VERSION ""

NS_ :

BS_:

BU_: GWM VCU

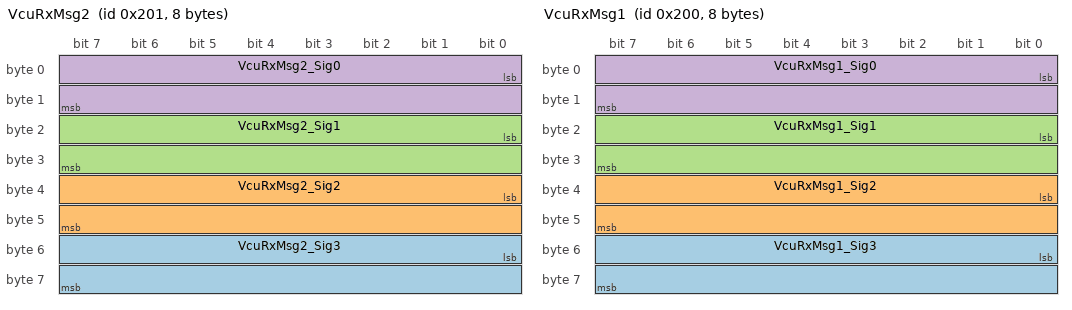
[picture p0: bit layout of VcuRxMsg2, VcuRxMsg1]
BO_ 513 VcuRxMsg2: 8 GWM
 SG_ VcuRxMsg2_Sig3 : 48|16@1- (1,0) [0|0] ""  VCU
 SG_ VcuRxMsg2_Sig2 : 32|16@1- (1,0) [0|0] ""  VCU
 SG_ VcuRxMsg2_Sig1 : 16|16@1- (1,0) [0|0] ""  VCU
 SG_ VcuRxMsg2_Sig0 : 0|16@1- (1,0) [0|0] ""  VCU

BO_ 512 VcuRxMsg1: 8 GWM
 SG_ VcuRxMsg1_Sig3 : 48|16@1- (1,0) [0|0] ""  VCU
 SG_ VcuRxMsg1_Sig2 : 32|16@1- (1,0) [0|0] ""  VCU
 SG_ VcuRxMsg1_Sig1 : 16|16@1- (1,0) [0|0] ""  VCU
 SG_ VcuRxMsg1_Sig0 : 0|16@1- (1,0) [0|0] ""  VCU

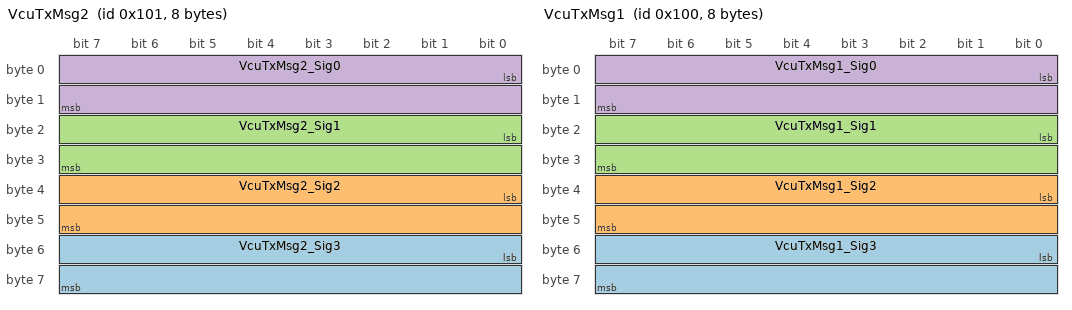
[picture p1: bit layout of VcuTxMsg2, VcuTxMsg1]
BO_ 257 VcuTxMsg2: 8 VCU
 SG_ VcuTxMsg2_Sig3 : 48|16@1- (1,0) [0|0] ""  GWM
 SG_ VcuTxMsg2_Sig2 : 32|16@1- (1,0) [0|0] ""  GWM
 SG_ VcuTxMsg2_Sig1 : 16|16@1- (1,0) [0|0] ""  GWM
 SG_ VcuTxMsg2_Sig0 : 0|16@1- (1,0) [0|0] ""  GWM

BO_ 256 VcuTxMsg1: 8 VCU
 SG_ VcuTxMsg1_Sig3 : 48|16@1- (1,0) [0|0] ""  GWM
 SG_ VcuTxMsg1_Sig2 : 32|16@1- (1,0) [0|0] ""  GWM
 SG_ VcuTxMsg1_Sig1 : 16|16@1- (1,0) [0|0] ""  GWM
 SG_ VcuTxMsg1_Sig0 : 0|16@1- (1,0) [0|0] ""  GWM

BO_ 1280 VCU_Rx_500h_NM: 8 GWM
 SG_ VCU_Rx_500h_NM : 0|64@1+ (1,0) [0|0] ""  VCU

BO_ 1308 VCU_Tx_51Ch_NM: 8 VCU
 SG_ VCU_Rx_51Fh_NM : 0|64@1+ (1,0) [0|0] ""  GWM

BA_DEF_ BO_  "GenMsgSendType" ENUM  "Cyclic","NotUsed","NotUsed","NotUsed","NotUsed","NotUsed","NotUsed","IfActive","NoMsgSendType","NotUsed";
BA_DEF_ BO_  "GenMsgCycleTime" INT 0 65535;
BA_DEF_ BO_  "CANFD_BRS" ENUM  "0","1";
BA_DEF_  "DBName" STRING ;
BA_DEF_  "BusType" STRING ;
BA_DEF_ BO_  "VFrameFormat" ENUM  "StandardCAN","ExtendedCAN","reserved","reserved","reserved","reserved","reserved","reserved","reserved","reserved","reserved","reserved","reserved","reserved","StandardCAN_FD","ExtendedCAN_FD";
BA_DEF_ BO_  "NmMessage" ENUM  "no","yes";
BA_DEF_  "NmAsrTimeoutTime" INT 1 65535;
BA_DEF_  "NmAsrMessageCount" INT 1 256;
BA_DEF_ BU_  "NmAsrCanMsgReducedTime" INT 1 65535;
BA_DEF_  "NmAsrCanMsgCycleTime" INT 1 65535;
BA_DEF_ BO_  "NmAsrMessage" ENUM  "no","yes";
BA_DEF_DEF_  "GenMsgSendType" "Cyclic";
BA_DEF_DEF_  "GenMsgCycleTime" 0;
BA_DEF_DEF_  "CANFD_BRS" "1";
BA_DEF_DEF_  "DBName" "";
BA_DEF_DEF_  "BusType" "";
BA_DEF_DEF_  "VFrameFormat" "StandardCAN";
BA_DEF_DEF_  "NmMessage" "";
BA_DEF_DEF_  "NmAsrTimeoutTime" 1;
BA_DEF_DEF_  "NmAsrMessageCount" 1;
BA_DEF_DEF_  "NmAsrCanMsgReducedTime" 1;
BA_DEF_DEF_  "NmAsrCanMsgCycleTime" 1;
BA_DEF_DEF_  "NmAsrMessage" "";
BA_ "BusType" "CAN FD";
BA_ "DBName" "CAN_FD";
BA_ "GenMsgCycleTime" BO_ 513 500;
BA_ "VFrameFormat" BO_ 513 14;
BA_ "GenMsgCycleTime" BO_ 512 500;
BA_ "VFrameFormat" BO_ 512 14;
BA_ "GenMsgCycleTime" BO_ 257 500;
BA_ "VFrameFormat" BO_ 257 14;
BA_ "GenMsgCycleTime" BO_ 256 500;
BA_ "VFrameFormat" BO_ 256 14;
BA_ "NmMessage" BO_ 1280 1;
BA_ "NmAsrMessage" BO_ 1280 1;
BA_ "GenMsgCycleTime" BO_ 1280 500;
BA_ "VFrameFormat" BO_ 1280 14;
BA_ "NmMessage" BO_ 1308 1;
BA_ "NmAsrMessage" BO_ 1308 1;
BA_ "GenMsgCycleTime" BO_ 1308 500;
BA_ "VFrameFormat" BO_ 1308 14;
